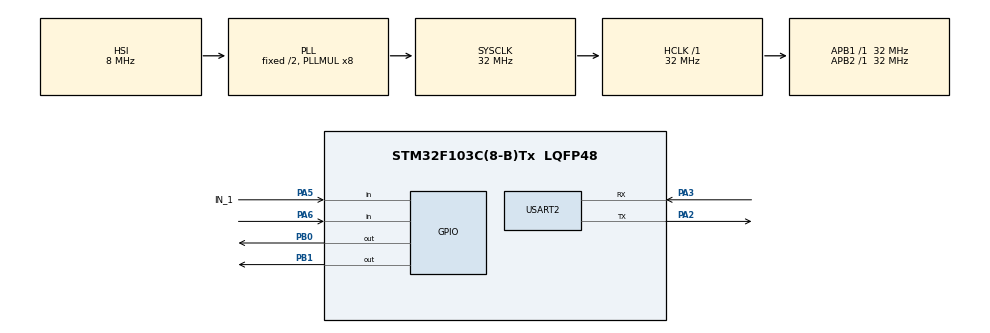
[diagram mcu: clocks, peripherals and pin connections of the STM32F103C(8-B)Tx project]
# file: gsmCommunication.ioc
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FREERTOS.Tasks01=defaultTask,0,128,StartDefaultTask,Default,NULL
Mcu.Family=STM32F1
Mcu.Name=STM32F103C(8-B)Tx
Mcu.Package=LQFP48
NVIC.PriorityGroup=NVIC_PRIORITYGROUP_4
NVIC.TIM1_UP_IRQn=true\:0\:0\:false\:false\:true\:false\:false
NVIC.TimeBase=TIM1_UP_IRQn
NVIC.TimeBaseIP=TIM1
PA13.Mode=Serial_Wire
PA13.Signal=SYS_JTMS-SWDIO
PA14.Mode=Serial_Wire
PA14.Signal=SYS_JTCK-SWCLK
PA2.Mode=Asynchronous
PA2.Signal=USART2_TX
PA3.Mode=Asynchronous
PA3.Signal=USART2_RX
PA5.GPIO_Label=IN_1
PA5.Signal=GPIO_Input
PA6.Signal=GPIO_Input
PB0.Signal=GPIO_Output
PB1.Signal=GPIO_Output
ProjectManager.HeapSize=0x200
ProjectManager.StackSize=0x400
ProjectManager.TargetToolchain=MDK-ARM V5
RCC.AHBFreq_Value=32000000
RCC.APB1Freq_Value=32000000
RCC.APB1TimFreq_Value=32000000
RCC.APB2Freq_Value=32000000
RCC.APB2TimFreq_Value=32000000
RCC.HCLKFreq_Value=32000000
RCC.PLLMUL=RCC_PLL_MUL8
RCC.SYSCLKFreq_VALUE=32000000
RCC.SYSCLKSource=RCC_SYSCLKSOURCE_PLLCLK
RCC.USBFreq_Value=32000000
USART2.VirtualMode=VM_ASYNC
VP_FREERTOS_VS_ENABLE.Mode=Enabled
VP_SYS_VS_tim1.Mode=TIM1
board=custom

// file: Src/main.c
/* USER CODE BEGIN Header */
/**
  ******************************************************************************
  * @file           : main.c
  * @brief          : Main program body
  ******************************************************************************
  * This notice applies to any and all portions of this file
  * that are not between comment pairs USER CODE BEGIN and
  * USER CODE END. Other portions of this file, whether
  * inserted by the user or by software development tools
  * are owned by their respective copyright owners.
  *
  * Copyright (c) 2019 STMicroelectronics International N.V.
  * All rights reserved.
  *
  * Redistribution and use in source and binary forms, with or without
  * modification, are permitted, provided that the following conditions are met:
  *
  * 1. Redistribution of source code must retain the above copyright notice,
  *    this list of conditions and the following disclaimer.
  * 2. Redistributions in binary form must reproduce the above copyright notice,
  *    this list of conditions and the following disclaimer in the documentation
  *    and/or other materials provided with the distribution.
  * 3. Neither the name of STMicroelectronics nor the names of other
  *    contributors to this software may be used to endorse or promote products
  *    derived from this software without specific written permission.
  * 4. This software, including modifications and/or derivative works of this
  *    software, must execute solely and exclusively on microcontroller or
  *    microprocessor devices manufactured by or for STMicroelectronics.
  * 5. Redistribution and use of this software other than as permitted under
  *    this license is void and will automatically terminate your rights under
  *    this license.
  *
  * THIS SOFTWARE IS PROVIDED BY STMICROELECTRONICS AND CONTRIBUTORS "AS IS"
  * AND ANY EXPRESS, IMPLIED OR STATUTORY WARRANTIES, INCLUDING, BUT NOT
  * LIMITED TO, THE IMPLIED WARRANTIES OF MERCHANTABILITY, FITNESS FOR A
  * PARTICULAR PURPOSE AND NON-INFRINGEMENT OF THIRD PARTY INTELLECTUAL PROPERTY
  * RIGHTS ARE DISCLAIMED TO THE FULLEST EXTENT PERMITTED BY LAW. IN NO EVENT
  * SHALL STMICROELECTRONICS OR CONTRIBUTORS BE LIABLE FOR ANY DIRECT, INDIRECT,
  * INCIDENTAL, SPECIAL, EXEMPLARY, OR CONSEQUENTIAL DAMAGES (INCLUDING, BUT NOT
  * LIMITED TO, PROCUREMENT OF SUBSTITUTE GOODS OR SERVICES; LOSS OF USE, DATA,
  * OR PROFITS; OR BUSINESS INTERRUPTION) HOWEVER CAUSED AND ON ANY THEORY OF
  * LIABILITY, WHETHER IN CONTRACT, STRICT LIABILITY, OR TORT (INCLUDING
  * NEGLIGENCE OR OTHERWISE) ARISING IN ANY WAY OUT OF THE USE OF THIS SOFTWARE,
  * EVEN IF ADVISED OF THE POSSIBILITY OF SUCH DAMAGE.
  *
  ******************************************************************************
  */
/* USER CODE END Header */

#include "main.h"
#include "cmsis_os.h"
#include "string.h"

UART_HandleTypeDef huart2;

osThreadId defaultTaskHandle;
osThreadId gsmTaskHandle;

void SystemClock_Config(void);
static void MX_GPIO_Init(void);
static void MX_USART2_UART_Init(void);
void StartDefaultTask(void const * argument);
void StartGSMTask(void const * argument);

int main(void)
{

  /* MCU Configuration--------------------------------------------------------*/

  /* Reset of all peripherals, Initializes the Flash interface and the Systick. */
  HAL_Init();

  /* Configure the system clock */
  SystemClock_Config();

  /* Initialize all configured peripherals */
  MX_GPIO_Init();
  MX_USART2_UART_Init();

  /* Create the thread(s) */
  /* definition and creation of defaultTask */
  osThreadDef(defaultTask, StartDefaultTask, osPriorityNormal, 0, 128);
  defaultTaskHandle = osThreadCreate(osThread(defaultTask), NULL);

  osThreadDef(gsmTask, StartGSMTask, osPriorityNormal, 0, 128);
  gsmTaskHandle = osThreadCreate(osThread(gsmTask), NULL);

  /* Start scheduler */
  osKernelStart();

  /* We should never get here as control is now taken by the scheduler */

  /* Infinite loop */
  while (1)
  {

  }
}

void SystemClock_Config(void)
{
  RCC_OscInitTypeDef RCC_OscInitStruct = {0};
  RCC_ClkInitTypeDef RCC_ClkInitStruct = {0};

  /**Initializes the CPU, AHB and APB busses clocks
  */
  RCC_OscInitStruct.OscillatorType = RCC_OSCILLATORTYPE_HSI;
  RCC_OscInitStruct.HSIState = RCC_HSI_ON;
  RCC_OscInitStruct.HSICalibrationValue = RCC_HSICALIBRATION_DEFAULT;
  RCC_OscInitStruct.PLL.PLLState = RCC_PLL_ON;
  RCC_OscInitStruct.PLL.PLLSource = RCC_PLLSOURCE_HSI_DIV2;
  RCC_OscInitStruct.PLL.PLLMUL = RCC_PLL_MUL8;
  if (HAL_RCC_OscConfig(&RCC_OscInitStruct) != HAL_OK)
  {
    Error_Handler();
  }
  /**Initializes the CPU, AHB and APB busses clocks
  */
  RCC_ClkInitStruct.ClockType = RCC_CLOCKTYPE_HCLK|RCC_CLOCKTYPE_SYSCLK
                              |RCC_CLOCKTYPE_PCLK1|RCC_CLOCKTYPE_PCLK2;
  RCC_ClkInitStruct.SYSCLKSource = RCC_SYSCLKSOURCE_PLLCLK;
  RCC_ClkInitStruct.AHBCLKDivider = RCC_SYSCLK_DIV1;
  RCC_ClkInitStruct.APB1CLKDivider = RCC_HCLK_DIV1;
  RCC_ClkInitStruct.APB2CLKDivider = RCC_HCLK_DIV1;

  if (HAL_RCC_ClockConfig(&RCC_ClkInitStruct, FLASH_LATENCY_1) != HAL_OK)
  {
    Error_Handler();
  }
}

static void MX_USART2_UART_Init(void)
{

  huart2.Instance = USART2;
  huart2.Init.BaudRate = 115200;
  huart2.Init.WordLength = UART_WORDLENGTH_8B;
  huart2.Init.StopBits = UART_STOPBITS_1;
  huart2.Init.Parity = UART_PARITY_NONE;
  huart2.Init.Mode = UART_MODE_TX_RX;
  huart2.Init.HwFlowCtl = UART_HWCONTROL_NONE;
  huart2.Init.OverSampling = UART_OVERSAMPLING_16;
  if (HAL_UART_Init(&huart2) != HAL_OK)
  {
    Error_Handler();
  }

}

static void MX_GPIO_Init(void)
{
  GPIO_InitTypeDef GPIO_InitStruct = {0};

  /* GPIO Ports Clock Enable */
  __HAL_RCC_GPIOA_CLK_ENABLE();
  __HAL_RCC_GPIOB_CLK_ENABLE();

  /*Configure GPIO pin Output Level */
  HAL_GPIO_WritePin(GPIOB, GPIO_PIN_0|GPIO_PIN_1, GPIO_PIN_RESET);

  /*Configure GPIO pins : IN_1_Pin PA6 */
  GPIO_InitStruct.Pin = IN_1_Pin|GPIO_PIN_6;
  GPIO_InitStruct.Mode = GPIO_MODE_INPUT;
  GPIO_InitStruct.Pull = GPIO_NOPULL;
  HAL_GPIO_Init(GPIOA, &GPIO_InitStruct);

  /*Configure GPIO pins : PB0 PB1 */
  GPIO_InitStruct.Pin = GPIO_PIN_0|GPIO_PIN_1;
  GPIO_InitStruct.Mode = GPIO_MODE_OUTPUT_PP;
  GPIO_InitStruct.Pull = GPIO_NOPULL;
  GPIO_InitStruct.Speed = GPIO_SPEED_FREQ_LOW;
  HAL_GPIO_Init(GPIOB, &GPIO_InitStruct);

}

/* USER CODE BEGIN 4 */
void debugPrintln(UART_HandleTypeDef *huart, char _out[]){
 HAL_UART_Transmit(huart, (uint8_t *) _out, strlen(_out), 10);
 char newline[2] = "\r\n";
 HAL_UART_Transmit(huart, (uint8_t *) newline, 2, 10);
}
/* USER CODE END 4 */

void StartDefaultTask(void const * argument)
{

  for(;;)
  {
	}
}
 void StartGSMTask(void const * argument)
 {
	  for(;;)
  {
		debugPrintln(&huart2, "how are you?"); // print full line
		osDelay(1000);
	}
 }

void HAL_TIM_PeriodElapsedCallback(TIM_HandleTypeDef *htim)
{
  if (htim->Instance == TIM1) {
    HAL_IncTick();
  }
}

void Error_Handler(void)
{
}

/************************ (C) COPYRIGHT STMicroelectronics *****END OF FILE****/
